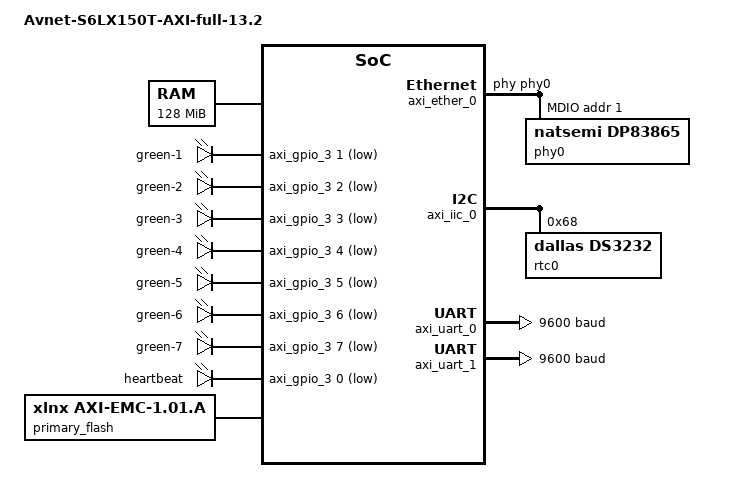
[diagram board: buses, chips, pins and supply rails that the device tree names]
/*
 * Device Tree Generator version: 1.03.a
 *
 * (C) Copyright 2007-2012 Xilinx, Inc.
 *
 * Based on original code:
 * (C) Copyright 2007-2011 PetaLogix Qld Pty Ltd
 *
 * (C) Copyright 2007-2010 Michal Simek
 * Michal SIMEK <monstr@monstr.eu>
 *
 * (C) Copyright 2010-2012 Li-Pro.Net
 * Stephan Linz <linz@li-pro.net>
 *
 * This program is free software; you can redistribute it and/or
 * modify it under the terms of the GNU General Public License as
 * published by the Free Software Foundation; either version 2 of
 * the License, or (at your option) any later version.
 *
 * This program is distributed in the hope that it will be useful,
 * but WITHOUT ANY WARRANTY; without even the implied warranty of
 * MERCHANTABILITY or FITNESS FOR A PARTICULAR PURPOSE. See the
 * GNU General Public License for more details.
 *
 * You should have received a copy of the GNU General Public License
 * along with this program; if not, write to the Free Software
 * Foundation, Inc., 59 Temple Place, Suite 330, Boston,
 * MA 02111-1307 USA
 *
 * CAUTION:  This file is automatically generated by libgen.
 * Version:  Xilinx EDK 13.2 EDK_O.61xd
 * Today is: Wednesday, the 16 of May, 2012; 20:01:10
 *
 * XPS project directory: Avnet-S6LX150T-AXI-full-13.2
 */

/dts-v1/;
/ {
	#address-cells = <1>;
	#size-cells = <1>;
	compatible = "xlnx,microblaze";
	hard-reset-gpios = < &axi_gpio_0 0 1 >;
	model = "Avnet-S6LX150T-AXI-full-13.2";
	aliases {
		ethernet0 = &axi_ether_0;
		serial0 = &axi_uart_0;
		serial1 = &axi_uart_1;
	} ;
	axi_s6_ddrx_0: memory@20000000 {
		device_type = "memory";
		reg = < 0x20000000 0x8000000 >;
	} ;
	chosen {
		bootargs = "console=ttyS0,115200 ubi.mtd=2 root=ubi0:root rootfstype=ubifs rw mtdparts=ae000000.flash:16384k(bpi),4096k(kernel),11776k(rootfs),384k(u-boot-xl)ro,128k(env) debug";
		linux,stdout-path = "/axi@0/serial@89ff0000";
	} ;
	cpus {
		#address-cells = <1>;
		#cpus = <0x1>;
		#size-cells = <0>;
		microblaze_0: cpu@0 {
			clock-frequency = <100000000>;
			compatible = "xlnx,microblaze-8.20.a";
			d-cache-baseaddr = <0x20000000>;
			d-cache-highaddr = <0x27ffffff>;
			d-cache-line-size = <0x10>;
			d-cache-size = <0x4000>;
			device_type = "cpu";
			i-cache-baseaddr = <0x20000000>;
			i-cache-highaddr = <0x27ffffff>;
			i-cache-line-size = <0x10>;
			i-cache-size = <0x4000>;
			model = "microblaze,8.20.a";
			reg = <0>;
			timebase-frequency = <100000000>;
			xlnx,addr-tag-bits = <0xd>;
			xlnx,allow-dcache-wr = <0x1>;
			xlnx,allow-icache-wr = <0x1>;
			xlnx,area-optimized = <0x0>;
			xlnx,avoid-primitives = <0x0>;
			xlnx,branch-target-cache-size = <0x0>;
			xlnx,cache-byte-size = <0x4000>;
			xlnx,d-axi = <0x1>;
			xlnx,d-lmb = <0x1>;
			xlnx,d-plb = <0x0>;
			xlnx,data-size = <0x20>;
			xlnx,dcache-addr-tag = <0xd>;
			xlnx,dcache-always-used = <0x1>;
			xlnx,dcache-byte-size = <0x4000>;
			xlnx,dcache-data-width = <0x0>;
			xlnx,dcache-force-tag-lutram = <0x0>;
			xlnx,dcache-interface = <0x0>;
			xlnx,dcache-line-len = <0x4>;
			xlnx,dcache-use-fsl = <0x0>;
			xlnx,dcache-use-writeback = <0x0>;
			xlnx,dcache-victims = <0x0>;
			xlnx,debug-enabled = <0x1>;
			xlnx,div-zero-exception = <0x1>;
			xlnx,dynamic-bus-sizing = <0x1>;
			xlnx,ecc-use-ce-exception = <0x0>;
			xlnx,edge-is-positive = <0x1>;
			xlnx,endianness = <0x1>;
			xlnx,family = "spartan6";
			xlnx,fault-tolerant = <0x0>;
			xlnx,fpu-exception = <0x1>;
			xlnx,freq = <0x5f5e100>;
			xlnx,fsl-data-size = <0x20>;
			xlnx,fsl-exception = <0x0>;
			xlnx,fsl-links = <0x0>;
			xlnx,i-axi = <0x1>;
			xlnx,i-lmb = <0x1>;
			xlnx,i-plb = <0x0>;
			xlnx,icache-always-used = <0x1>;
			xlnx,icache-data-width = <0x0>;
			xlnx,icache-force-tag-lutram = <0x0>;
			xlnx,icache-interface = <0x0>;
			xlnx,icache-line-len = <0x4>;
			xlnx,icache-streams = <0x0>;
			xlnx,icache-use-fsl = <0x0>;
			xlnx,icache-victims = <0x0>;
			xlnx,ill-opcode-exception = <0x1>;
			xlnx,instance = "microblaze_0";
			xlnx,interconnect = <0x2>;
			xlnx,interrupt-is-edge = <0x0>;
			xlnx,lockstep-slave = <0x0>;
			xlnx,mmu-dtlb-size = <0x4>;
			xlnx,mmu-itlb-size = <0x2>;
			xlnx,mmu-privileged-instr = <0x0>;
			xlnx,mmu-tlb-access = <0x3>;
			xlnx,mmu-zones = <0x2>;
			xlnx,number-of-pc-brk = <0x1>;
			xlnx,number-of-rd-addr-brk = <0x0>;
			xlnx,number-of-wr-addr-brk = <0x0>;
			xlnx,opcode-0x0-illegal = <0x1>;
			xlnx,optimization = <0x0>;
			xlnx,pvr = <0x2>;
			xlnx,pvr-user1 = <0x0>;
			xlnx,pvr-user2 = <0x0>;
			xlnx,reset-msr = <0x0>;
			xlnx,sco = <0x0>;
			xlnx,stream-interconnect = <0x0>;
			xlnx,unaligned-exceptions = <0x1>;
			xlnx,use-barrel = <0x1>;
			xlnx,use-branch-target-cache = <0x0>;
			xlnx,use-dcache = <0x1>;
			xlnx,use-div = <0x1>;
			xlnx,use-ext-brk = <0x1>;
			xlnx,use-ext-nm-brk = <0x1>;
			xlnx,use-extended-fsl-instr = <0x0>;
			xlnx,use-fpu = <0x1>;
			xlnx,use-hw-mul = <0x1>;
			xlnx,use-icache = <0x1>;
			xlnx,use-interrupt = <0x1>;
			xlnx,use-mmu = <0x3>;
			xlnx,use-msr-instr = <0x1>;
			xlnx,use-pcmp-instr = <0x1>;
			xlnx,use-stack-protection = <0x0>;
		} ;
	} ;
	axi4lite_0: axi@0 {
		#address-cells = <1>;
		#size-cells = <1>;
		compatible = "xlnx,axi-interconnect-1.03.a", "simple-bus";
		ranges ;
		axi_dma_0: axi-dma@8adf0000 {
			compatible = "xlnx,axi-dma-4.00.a", "xlnx,axi-dma-1.00.a";
			interrupt-parent = <&axi_intc_0>;
			interrupts = < 3 2 2 2 >;
			reg = < 0x8adf0000 0x10000 >;
			xlnx,dlytmr-resolution = <0x4e2>;
			xlnx,family = "spartan6";
			xlnx,include-mm2s = <0x1>;
			xlnx,include-mm2s-dre = <0x1>;
			xlnx,include-s2mm = <0x1>;
			xlnx,include-s2mm-dre = <0x1>;
			xlnx,include-sg = <0x1>;
			xlnx,mm2s-burst-size = <0x10>;
			xlnx,prmry-is-aclk-async = <0x0>;
			xlnx,s2mm-burst-size = <0x10>;
			xlnx,sg-include-desc-queue = <0x1>;
			xlnx,sg-include-stscntrl-strm = <0x1>;
			xlnx,sg-length-width = <0x10>;
			xlnx,sg-use-stsapp-length = <0x1>;
		} ;
		axi_ether_0: axi-ethernet@88f00000 {
			axistream-connected = <&axi_dma_0>;
			compatible = "xlnx,axi-ethernet-3.00.a", "xlnx,axi-ethernet-1.00.a";
			device_type = "network";
			interrupt-parent = <&axi_intc_0>;
			interrupts = < 4 2 >;
			local-mac-address = [ 00 0a 35 66 00 00 ];
			phy-handle = <&phy0>;
			reg = < 0x88f00000 0x40000 >;
			xlnx,avb = <0x0>;
			xlnx,halfdup = <0x0>;
			xlnx,include-io = <0x1>;
			xlnx,mcast-extend = <0x0>;
			xlnx,phy-type = <0x1>;
			xlnx,phyaddr = "0B00001";
			xlnx,rxcsum = <0x0>;
			xlnx,rxmem = <0x1000>;
			xlnx,rxvlan-strp = <0x0>;
			xlnx,rxvlan-tag = <0x0>;
			xlnx,rxvlan-tran = <0x0>;
			xlnx,stats = <0x0>;
			xlnx,txcsum = <0x0>;
			xlnx,txmem = <0x1000>;
			xlnx,txvlan-strp = <0x0>;
			xlnx,txvlan-tag = <0x0>;
			xlnx,txvlan-tran = <0x0>;
			xlnx,type = <0x1>;
			mdio {
				#address-cells = <1>;
				#size-cells = <0>;
				phy0: phy@1 {
					compatible = "natsemi,dp83865";
					device_type = "ethernet-phy";
					reg = <1>;
				} ;
			} ;
		} ;
		axi_gpio_0: gpio@80ff0000 {
			#gpio-cells = <2>;
			compatible = "xlnx,axi-gpio-1.01.a", "xlnx,xps-gpio-1.00.a";
			gpio-controller ;
			reg = < 0x80ff0000 0x10000 >;
			xlnx,all-inputs = <0x0>;
			xlnx,all-inputs-2 = <0x0>;
			xlnx,dout-default = <0x0>;
			xlnx,dout-default-2 = <0x0>;
			xlnx,family = "spartan6";
			xlnx,gpio-width = <0x1>;
			xlnx,gpio2-width = <0x20>;
			xlnx,interrupt-present = <0x0>;
			xlnx,is-dual = <0x0>;
			xlnx,tri-default = <0xffffffff>;
			xlnx,tri-default-2 = <0xffffffff>;
		} ;
		axi_gpio_1: gpio@80fe0000 {
			#gpio-cells = <2>;
			compatible = "xlnx,axi-gpio-1.01.a", "xlnx,xps-gpio-1.00.a";
			gpio-controller ;
			reg = < 0x80fe0000 0x10000 >;
			xlnx,all-inputs = <0x1>;
			xlnx,all-inputs-2 = <0x0>;
			xlnx,dout-default = <0x0>;
			xlnx,dout-default-2 = <0x0>;
			xlnx,family = "spartan6";
			xlnx,gpio-width = <0x3>;
			xlnx,gpio2-width = <0x20>;
			xlnx,interrupt-present = <0x0>;
			xlnx,is-dual = <0x0>;
			xlnx,tri-default = <0xffffffff>;
			xlnx,tri-default-2 = <0xffffffff>;
		} ;
		axi_gpio_2: gpio@80fd0000 {
			#gpio-cells = <2>;
			compatible = "xlnx,axi-gpio-1.01.a", "xlnx,xps-gpio-1.00.a";
			gpio-controller ;
			reg = < 0x80fd0000 0x10000 >;
			xlnx,all-inputs = <0x1>;
			xlnx,all-inputs-2 = <0x0>;
			xlnx,dout-default = <0x0>;
			xlnx,dout-default-2 = <0x0>;
			xlnx,family = "spartan6";
			xlnx,gpio-width = <0x8>;
			xlnx,gpio2-width = <0x20>;
			xlnx,interrupt-present = <0x0>;
			xlnx,is-dual = <0x0>;
			xlnx,tri-default = <0xffffffff>;
			xlnx,tri-default-2 = <0xffffffff>;
		} ;
		axi_gpio_3: gpio@80fc0000 {
			#gpio-cells = <2>;
			compatible = "xlnx,axi-gpio-1.01.a", "xlnx,xps-gpio-1.00.a";
			gpio-controller ;
			reg = < 0x80fc0000 0x10000 >;
			xlnx,all-inputs = <0x0>;
			xlnx,all-inputs-2 = <0x0>;
			xlnx,dout-default = <0x0>;
			xlnx,dout-default-2 = <0x0>;
			xlnx,family = "spartan6";
			xlnx,gpio-width = <0x8>;
			xlnx,gpio2-width = <0x20>;
			xlnx,interrupt-present = <0x0>;
			xlnx,is-dual = <0x0>;
			xlnx,tri-default = <0xffffffff>;
			xlnx,tri-default-2 = <0xffffffff>;
		} ;
		axi_iic_0: i2c@80ef0000 {
			#address-cells = <1>;
			#size-cells = <0>;
			compatible = "xlnx,axi-iic-1.01.a", "xlnx,xps-iic-2.00.a";
			interrupt-parent = <&axi_intc_0>;
			interrupts = < 7 2 >;
			reg = < 0x80ef0000 0x10000 >;
			xlnx,family = "spartan6";
			xlnx,gpo-width = <0x1>;
			xlnx,iic-freq = <0x186a0>;
			xlnx,scl-inertial-delay = <0x0>;
			xlnx,sda-inertial-delay = <0x0>;
			xlnx,sda-level = <0x1>;
			xlnx,ten-bit-adr = <0x0>;
			rtc0: rtc@68 {
				compatible = "dallas,ds3232";
				reg = <0x68>;
				interrupt-parent = <&axi_intc_0>;
				interrupts = < 1 1 >;
			};
		} ;
		axi_intc_0: interrupt-controller@8aff0000 {
			#interrupt-cells = <0x2>;
			compatible = "xlnx,axi-intc-1.01.a", "xlnx,xps-intc-1.00.a";
			interrupt-controller ;
			reg = < 0x8aff0000 0x10000 >;
			xlnx,kind-of-intr = <0x0>;
			xlnx,num-intr-inputs = <0x8>;
		} ;
		axi_timer_0: system-timer@8aef0000 {
			clock-frequency = <100000000>;
			compatible = "xlnx,axi-timer-1.02.a", "xlnx,xps-timer-1.00.a";
			interrupt-parent = <&axi_intc_0>;
			interrupts = < 0 2 >;
			reg = < 0x8aef0000 0x10000 >;
			xlnx,count-width = <0x20>;
			xlnx,family = "spartan6";
			xlnx,gen0-assert = <0x1>;
			xlnx,gen1-assert = <0x1>;
			xlnx,one-timer-only = <0x0>;
			xlnx,trig0-assert = <0x1>;
			xlnx,trig1-assert = <0x1>;
		} ;
		axi_uart_0: serial@89ff0000 {
			clock-frequency = <100000000>;
			compatible = "xlnx,axi-uart16550-1.01.a", "xlnx,xps-uart16550-2.00.a", "ns16550a";
			current-speed = <9600>;
			device_type = "serial";
			interrupt-parent = <&axi_intc_0>;
			interrupts = < 5 2 >;
			reg = < 0x89ff0000 0x10000 >;
			reg-offset = <0x1000>;
			reg-shift = <2>;
			xlnx,external-xin-clk-hz = <0x17d7840>;
			xlnx,family = "spartan6";
			xlnx,has-external-rclk = <0x0>;
			xlnx,has-external-xin = <0x0>;
			xlnx,is-a-16550 = <0x1>;
			xlnx,use-modem-ports = <0x0>;
			xlnx,use-user-ports = <0x0>;
		} ;
		axi_uart_1: serial@89fe0000 {
			clock-frequency = <100000000>;
			compatible = "xlnx,axi-uart16550-1.01.a", "xlnx,xps-uart16550-2.00.a", "ns16550a";
			current-speed = <9600>;
			device_type = "serial";
			interrupt-parent = <&axi_intc_0>;
			interrupts = < 6 2 >;
			reg = < 0x89fe0000 0x10000 >;
			reg-offset = <0x1000>;
			reg-shift = <2>;
			xlnx,external-xin-clk-hz = <0x17d7840>;
			xlnx,family = "spartan6";
			xlnx,has-external-rclk = <0x0>;
			xlnx,has-external-xin = <0x0>;
			xlnx,is-a-16550 = <0x1>;
			xlnx,use-modem-ports = <0x0>;
			xlnx,use-user-ports = <0x0>;
		} ;
		gpio-leds {
			compatible = "gpio-leds";
			green-1 {
				gpios = < &axi_gpio_3 1 1 >;
				label = "green-1";
			} ;
			green-2 {
				gpios = < &axi_gpio_3 2 1 >;
				label = "green-2";
			} ;
			green-3 {
				gpios = < &axi_gpio_3 3 1 >;
				label = "green-3";
			} ;
			green-4 {
				gpios = < &axi_gpio_3 4 1 >;
				label = "green-4";
			} ;
			green-5 {
				gpios = < &axi_gpio_3 5 1 >;
				label = "green-5";
			} ;
			green-6 {
				gpios = < &axi_gpio_3 6 1 >;
				label = "green-6";
			} ;
			green-7 {
				gpios = < &axi_gpio_3 7 1 >;
				label = "green-7";
			} ;
			heartbeat {
				gpios = < &axi_gpio_3 0 1 >;
				label = "heartbeat";
				linux,default-trigger = "heartbeat";
			} ;
		} ;
		mbref_mio_0: uio@80410000 {
			compatible = "xlnx,axi-mbref-mio-1.00.a", "generic-uio";
			reg = < 0x80410000 0x1000 0x80411000 0x1000 0x80412000 0x1000 0x80413000 0x1000 >;
			xlnx,align-be-rdaddr = <0x0>;
			xlnx,family = "spartan6";
			xlnx,include-timeout-cnt = <0x1>;
			xlnx,rdata-fifo-depth = <0x0>;
			xlnx,s-axi-id-width = <0x1>;
			xlnx,s-axi-supports-read = <0x1>;
			xlnx,s-axi-supports-write = <0x1>;
			xlnx,timeout-cntr-val = <0x8>;
		} ;
		mbref_reg_0: uio@80800000 {
			compatible = "xlnx,axi-mbref-reg-1.00.a", "generic-uio";
			reg = < 0x80800000 0x10000 >;
			xlnx,dphase-timeout = <0x8>;
			xlnx,family = "spartan6";
			xlnx,num-mem = <0x1>;
			xlnx,num-reg = <0x1>;
			xlnx,s-axi-min-size = <0x1ff>;
			xlnx,slv-awidth = <0x20>;
			xlnx,slv-dwidth = <0x20>;
			xlnx,use-wstrb = <0x0>;
		} ;
		mdm_0: debug@8fff0000 {
			compatible = "xlnx,mdm-2.00.b", "xlnx,xps-uartlite-1.00.a";
			reg = < 0x8fff0000 0x10000 >;
			xlnx,family = "spartan6";
			xlnx,interconnect = <0x2>;
			xlnx,jtag-chain = <0x2>;
			xlnx,mb-dbg-ports = <0x1>;
			xlnx,use-uart = <0x1>;
		} ;
		primary_flash: flash@ae000000 {
			bank-width = <2>;
			compatible = "xlnx,axi-emc-1.01.a", "cfi-flash";
			reg = < 0xae000000 0x2000000 >;
			xlnx,axi-clk-period-ps = <0x2710>;
			xlnx,family = "spartan6";
			xlnx,include-datawidth-matching-0 = <0x1>;
			xlnx,include-datawidth-matching-1 = <0x0>;
			xlnx,include-datawidth-matching-2 = <0x0>;
			xlnx,include-datawidth-matching-3 = <0x0>;
			xlnx,include-negedge-ioregs = <0x0>;
			xlnx,max-mem-width = <0x10>;
			xlnx,mem0-type = <0x2>;
			xlnx,mem0-width = <0x10>;
			xlnx,mem1-type = <0x0>;
			xlnx,mem1-width = <0x20>;
			xlnx,mem2-type = <0x0>;
			xlnx,mem2-width = <0x20>;
			xlnx,mem3-type = <0x0>;
			xlnx,mem3-width = <0x20>;
			xlnx,num-banks-mem = <0x1>;
			xlnx,parity-type-mem-0 = <0x0>;
			xlnx,parity-type-mem-1 = <0x0>;
			xlnx,parity-type-mem-2 = <0x0>;
			xlnx,parity-type-mem-3 = <0x0>;
			xlnx,s-axi-en-reg = <0x0>;
			xlnx,s-axi-mem-addr-width = <0x20>;
			xlnx,s-axi-mem-data-width = <0x20>;
			xlnx,s-axi-mem-id-width = <0x1>;
			xlnx,s-axi-mem-protocol = "AXI4LITE";
			xlnx,s-axi-reg-addr-width = <0x20>;
			xlnx,s-axi-reg-data-width = <0x20>;
			xlnx,s-axi-reg-protocol = "axi4";
			xlnx,synch-pipedelay-0 = <0x2>;
			xlnx,synch-pipedelay-1 = <0x2>;
			xlnx,synch-pipedelay-2 = <0x2>;
			xlnx,synch-pipedelay-3 = <0x2>;
			xlnx,tavdv-ps-mem-0 = <0x1fbd0>;
			xlnx,tavdv-ps-mem-1 = <0x3a98>;
			xlnx,tavdv-ps-mem-2 = <0x3a98>;
			xlnx,tavdv-ps-mem-3 = <0x3a98>;
			xlnx,tcedv-ps-mem-0 = <0x1fbd0>;
			xlnx,tcedv-ps-mem-1 = <0x3a98>;
			xlnx,tcedv-ps-mem-2 = <0x3a98>;
			xlnx,tcedv-ps-mem-3 = <0x3a98>;
			xlnx,thzce-ps-mem-0 = <0x88b8>;
			xlnx,thzce-ps-mem-1 = <0x1b58>;
			xlnx,thzce-ps-mem-2 = <0x1b58>;
			xlnx,thzce-ps-mem-3 = <0x1b58>;
			xlnx,thzoe-ps-mem-0 = <0x1b58>;
			xlnx,thzoe-ps-mem-1 = <0x1b58>;
			xlnx,thzoe-ps-mem-2 = <0x1b58>;
			xlnx,thzoe-ps-mem-3 = <0x1b58>;
			xlnx,tlzwe-ps-mem-0 = <0x88b8>;
			xlnx,tlzwe-ps-mem-1 = <0x0>;
			xlnx,tlzwe-ps-mem-2 = <0x0>;
			xlnx,tlzwe-ps-mem-3 = <0x0>;
			xlnx,tpacc-ps-flash-0 = <0x61a8>;
			xlnx,tpacc-ps-flash-1 = <0x61a8>;
			xlnx,tpacc-ps-flash-2 = <0x61a8>;
			xlnx,tpacc-ps-flash-3 = <0x61a8>;
			xlnx,twc-ps-mem-0 = <0x32c8>;
			xlnx,twc-ps-mem-1 = <0x3a98>;
			xlnx,twc-ps-mem-2 = <0x3a98>;
			xlnx,twc-ps-mem-3 = <0x3a98>;
			xlnx,twp-ps-mem-0 = <0x11170>;
			xlnx,twp-ps-mem-1 = <0x2ee0>;
			xlnx,twp-ps-mem-2 = <0x2ee0>;
			xlnx,twp-ps-mem-3 = <0x2ee0>;
			xlnx,twph-ps-mem-0 = <0x2ee0>;
			xlnx,twph-ps-mem-1 = <0x2ee0>;
			xlnx,twph-ps-mem-2 = <0x2ee0>;
			xlnx,twph-ps-mem-3 = <0x2ee0>;
		} ;
	} ;
} ;
